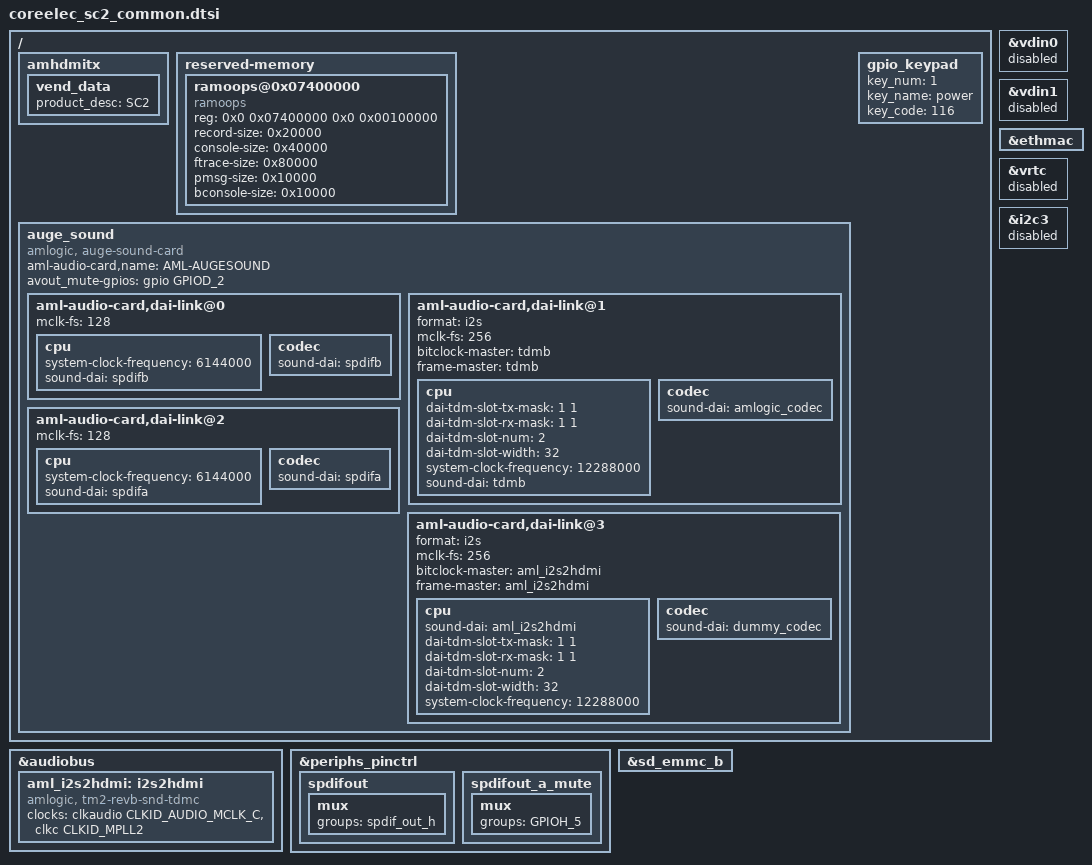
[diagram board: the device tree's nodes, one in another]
#include "coreelec_common.dtsi"

/ {
	amhdmitx: amhdmitx{
		vend_data: vend_data{ /* Should modified by Customer */
			product_desc = "SC2"; /* Max Chars: 16 */
		};
	};

	reserved-memory {
		ramoops@0x07400000 {
			compatible = "ramoops";
			reg = <0x0 0x07400000 0x0 0x00100000>;
			record-size = <0x20000>;
			console-size = <0x40000>;
			ftrace-size = <0x80000>;
			pmsg-size = <0x10000>;
			bconsole-size = <0x10000>;
		};
	};

	/delete-node/ auge_sound;
	auge_sound {
		compatible = "amlogic, auge-sound-card";
		aml-audio-card,name = "AML-AUGESOUND";

		/*avout mute gpio*/
		avout_mute-gpios = <&gpio GPIOD_2 GPIO_ACTIVE_HIGH>;

		aml-audio-card,dai-link@0 {
			mclk-fs = <128>;
			cpu {
				system-clock-frequency = <6144000>;
				sound-dai = <&spdifb>;
			};
			codec {
				sound-dai = <&spdifb>;
			};
		};

		aml-audio-card,dai-link@1 {
			format = "i2s";
			mclk-fs = <256>;
			bitclock-master = <&tdmb>;
			frame-master = <&tdmb>;
			cpu {
				dai-tdm-slot-tx-mask = <1 1>;
				dai-tdm-slot-rx-mask = <1 1>;
				dai-tdm-slot-num = <2>;
				dai-tdm-slot-width = <32>;
				system-clock-frequency = <12288000>;
				sound-dai = <&tdmb>;
			};
			codec {
				sound-dai = <&amlogic_codec>;
			};
		};

		aml-audio-card,dai-link@2 {
			mclk-fs = <128>;
			cpu {
				system-clock-frequency = <6144000>;
				sound-dai = <&spdifa>;
			};
			codec {
				sound-dai = <&spdifa>;
			};
		};

		aml-audio-card,dai-link@3 {
			format = "i2s";
			mclk-fs = <256>;
			bitclock-master = <&aml_i2s2hdmi>;
			frame-master = <&aml_i2s2hdmi>;
			cpu {
				sound-dai = <&aml_i2s2hdmi>;
				dai-tdm-slot-tx-mask = <1 1>;
				dai-tdm-slot-rx-mask = <1 1>;
				dai-tdm-slot-num = <2>;
				dai-tdm-slot-width = <32>;
				system-clock-frequency = <12288000>;
			};
			codec {
				sound-dai = <&dummy_codec>;
			};
		};
	};

	gpio_keypad {
		key_num = <1>;
		key_name = "power";
		key_code = <116>;
	};
};

&vdin0 {
	status = "disabled";
};

&vdin1 {
	status = "disabled";
};

&ethmac {
	status = "okay";
};

&audiobus {
	aml_i2s2hdmi: i2s2hdmi {
		compatible = "amlogic, tm2-revb-snd-tdmc";
		clocks = <&clkaudio CLKID_AUDIO_MCLK_C
				&clkc CLKID_MPLL2>;
		clock-names = "mclk", "clk_srcpll";
	};
};

&periphs_pinctrl {
	spdifout: spdifout {
		mux { /* GPIOH_4 */
			groups = "spdif_out_h";
		};
	};

	spdifout_a_mute: spdifout_a_mute {
		mux { /* GPIOH_5 */
			groups = "GPIOH_5";
		};
	};
};

&vrtc {
	status = "disabled";
};

&i2c3 {
	status = "disabled";
	/delete-node/ tlc59116@60;
};

&sd_emmc_b {
	status = "okay";
};
